AUTOSAR XML (schema 00050)
standard types defined: Boolean
package /ARRoot
  application-sw-component-type:
    provide port BlindSpotDetection
    provide port Defogger
    provide port Display
    require port Sensor
    behavior SideMirrorIB
      4 x runnable:
        BlindSpotDetectionRunnable: synchronous-server-call-point
        DefoggerRunnable: synchronous-server-call-point
        DisplayRunnable: variable-access
        SensorRunnable: variable-access
  client server interface BlindSpotDetection: client-server-operation=arguments=argument-data-prototype=type=Boolean
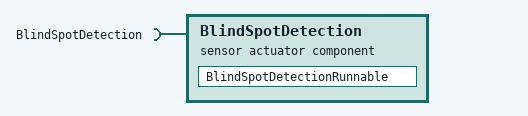
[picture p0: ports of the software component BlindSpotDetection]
  sensor actuator sw component type BlindSpotDetection
    require port BlindSpotDetection
    behavior BlindSpotDetectionIB
      runnable BlindSpotDetectionRunnable: synchronous-server-call-point=BlindSpotDetection.
  swc implementation BlindSpotDetectionIMP: programming-language=C, behavior=BlindSpotDetectionIB
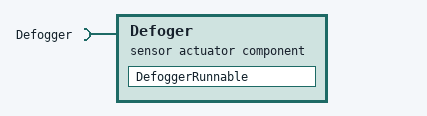
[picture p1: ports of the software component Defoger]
  sensor actuator sw component type Defoger
    require port Defogger
    behavior DefoggerIB
      runnable DefoggerRunnable: synchronous-server-call-point=Defogger.
  client server interface Defogger: client-server-operation=arguments=argument-data-prototype=type=Boolean
  swc implementation DefoggerIMP: programming-language=C, behavior=DefoggerIB
  sender receiver interface Display
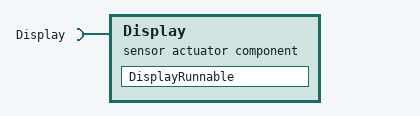
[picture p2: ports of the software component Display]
  sensor actuator sw component type Display
    require port Display
    behavior DisplayIB
      runnable DisplayRunnable: variable-access=accessed-variable=/ARRoot/Display/
  swc implementation DisplayIMP: programming-language=C, behavior=DisplayIB
  sender receiver interface Sensor
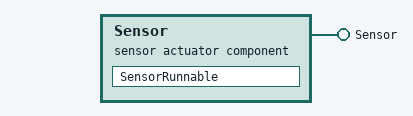
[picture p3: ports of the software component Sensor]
  sensor actuator sw component type Sensor
    provide port Sensor
    behavior SensorIB
      runnable SensorRunnable: variable-access=accessed-variable=/ARRoot/Sensor/
  swc implementation SensorIMP: programming-language=C, behavior=SensorIB
